VERSION ""

NS_ :

BS_:

BU_:

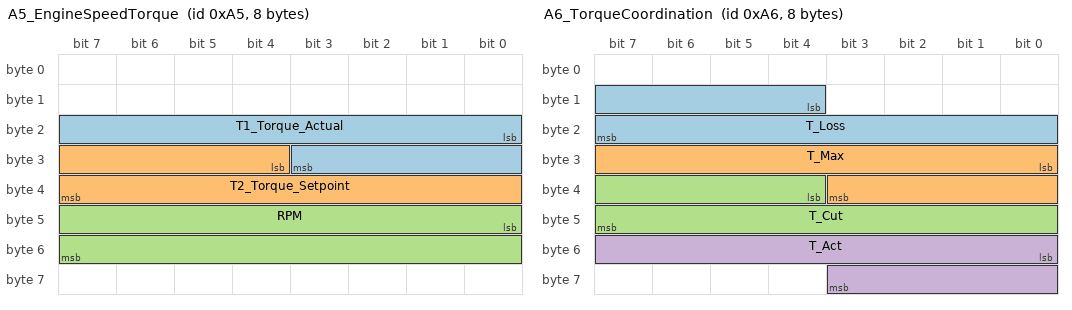
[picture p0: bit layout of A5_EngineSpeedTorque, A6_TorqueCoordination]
BO_ 165 A5_EngineSpeedTorque: 8 Vector__XXX
 SG_ T1_Torque_Actual   : 16|12@1+ (0.5,-999.5) [-999.5|1048.0] "Nm" Vector__XXX
 SG_ T2_Torque_Setpoint : 28|12@1+ (0.5,-999.5) [-999.5|1048.0] "Nm" Vector__XXX
 SG_ RPM                : 40|16@1+ (0.25,0)     [0|16383.75]    "rpm" Vector__XXX

BO_ 166 A6_TorqueCoordination: 8 Vector__XXX
 SG_ T_Loss : 12|12@1+ (0.5,-999.5) [-999.5|1048.0] "Nm" Vector__XXX
 SG_ T_Max  : 24|12@1+ (0.5,-999.5) [-999.5|1048.0] "Nm" Vector__XXX
 SG_ T_Cut  : 36|12@1+ (0.5,-999.5) [-999.5|1048.0] "Nm" Vector__XXX
 SG_ T_Act  : 48|12@1+ (0.5,-999.5) [-999.5|1048.0] "Nm" Vector__XXX

BO_ 167 A7_AirFuelManagement: 7 Vector__XXX
 SG_ T_Demand : 12|12@1+ (0.5,-999.5) [-999.5|1048.0] "Nm" Vector__XXX
 SG_ A7_Sig2  : 32|16@1+ (0.125,-3991.5) [-999.5|1048.0] "Nm" Vector__XXX

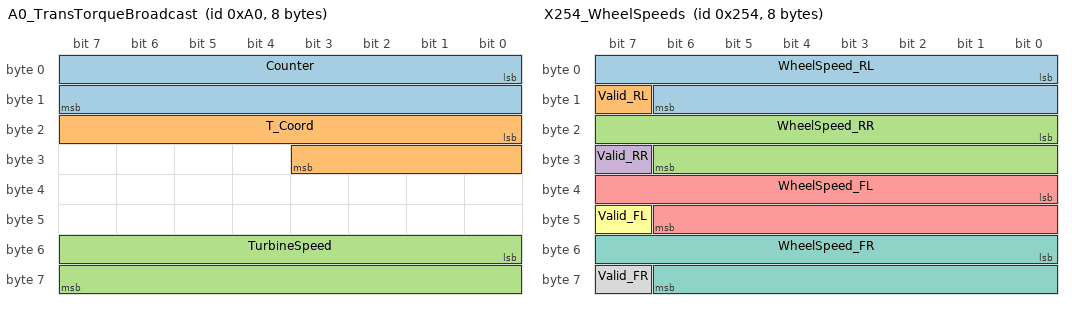
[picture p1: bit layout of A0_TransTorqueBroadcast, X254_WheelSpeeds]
BO_ 160 A0_TransTorqueBroadcast: 8 Vector__XXX
 SG_ Counter      :  0|16@1+ (1,0)        [0|65535]       ""    Vector__XXX
 SG_ T_Coord      : 16|12@1+ (0.5,-999.5) [-999.5|1048.0] "Nm"  Vector__XXX
 SG_ TurbineSpeed : 48|16@1+ (1,-2000)    [0|14000]        "rpm" Vector__XXX

BO_ 176 B0_TransTorqueMgmt: 8 Vector__XXX
 SG_ AliveCounter  :  0|16@1+ (1,0)        [0|65535]       ""   Vector__XXX
 SG_ B0_T1         : 12|12@1+ (0.5,-999.5) [-999.5|1048.0] "Nm" Vector__XXX
 SG_ B0_ShiftCeil  : 24|12@1+ (0.5,-999.5) [-999.5|1048.0] "Nm" Vector__XXX
 SG_ B0_T3         : 36|12@1+ (0.5,-999.5) [-999.5|1048.0] "Nm" Vector__XXX

BO_ 143 X8F_TorqueSignal: 8 Vector__XXX
 SG_ X8F_Sig1 : 16|16@1+ (0.125,-3991.5) [-999.5|1048.0] "Nm" Vector__XXX

BO_ 217 D9_PedalPosition: 8 Vector__XXX
 SG_ Pedal_Raw : 16|12@1+ (1,0) [0|4095] "" Vector__XXX

BO_ 596 X254_WheelSpeeds: 8 Vector__XXX
 SG_ WheelSpeed_RL : 0|15@1+  (1,0) [0|32767] "grad/s" Vector__XXX
 SG_ Valid_RL      : 15|1@1+  (1,0) [0|1]     ""        Vector__XXX
 SG_ WheelSpeed_RR : 16|15@1+ (1,0) [0|32767] "grad/s" Vector__XXX
 SG_ Valid_RR      : 31|1@1+  (1,0) [0|1]     ""        Vector__XXX
 SG_ WheelSpeed_FL : 32|15@1+ (1,0) [0|32767] "grad/s" Vector__XXX
 SG_ Valid_FL      : 47|1@1+  (1,0) [0|1]     ""        Vector__XXX
 SG_ WheelSpeed_FR : 48|15@1+ (1,0) [0|32767] "grad/s" Vector__XXX
 SG_ Valid_FR      : 63|1@1+  (1,0) [0|1]     ""        Vector__XXX

CM_ BO_ 596 "Wheel speed broadcast. 4 x uint15 wheel speeds in gradians/second (400 gradians = 1 wheel revolution). Field order is RL, RR, FL, FR (rear axle precedes front). Bit 15 of each 16-bit field is a 'valid' flag (1 = valid). Invalid pattern: lower 15 bits all set (0x7FFF). wheel_rpm = raw * 60 / 400 = raw * 0.15. Final-drive ratio = tailshaft_rpm / wheel_rpm. The RL/RR-first ordering was confirmed by the F20 dyno capture, where only the driven (rear) wheels remain valid while the lifted front wheels are flagged invalid.";
